VERSION ""

NS_ :

BS_:

BU_: New_Node_1

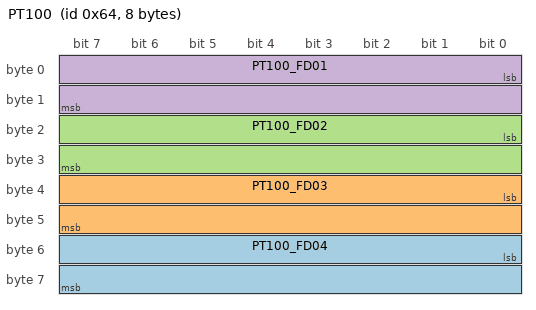
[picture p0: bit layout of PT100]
BO_ 100 PT100: 8 Vector__XXX
 SG_ PT100_FD04 : 48|16@1- (0.1,0) [0|0] ""  New_Node_1
 SG_ PT100_FD03 : 32|16@1- (0.1,0) [0|0] ""  New_Node_1
 SG_ PT100_FD02 : 16|16@1- (0.1,0) [0|0] ""  New_Node_1
 SG_ PT100_FD01 : 0|16@1- (0.1,0) [0|0] ""  New_Node_1

BA_DEF_ BO_  "CANFD_BRS" ENUM  "0","1";
BA_DEF_  "DBName" STRING ;
BA_DEF_  "BusType" STRING ;
BA_DEF_ BO_  "VFrameFormat" ENUM  "StandardCAN","ExtendedCAN","reserved","reserved","reserved","reserved","reserved","reserved","reserved","reserved","reserved","reserved","reserved","reserved","StandardCAN_FD","ExtendedCAN_FD";
BA_DEF_DEF_  "CANFD_BRS" "1";
BA_DEF_DEF_  "DBName" "";
BA_DEF_DEF_  "BusType" "";
BA_DEF_DEF_  "VFrameFormat" "StandardCAN";
BA_ "BusType" "CAN FD";
BA_ "DBName" "CANFD";
